AUTOSAR XML (schema 4-0-3)
package /ComponentTypes
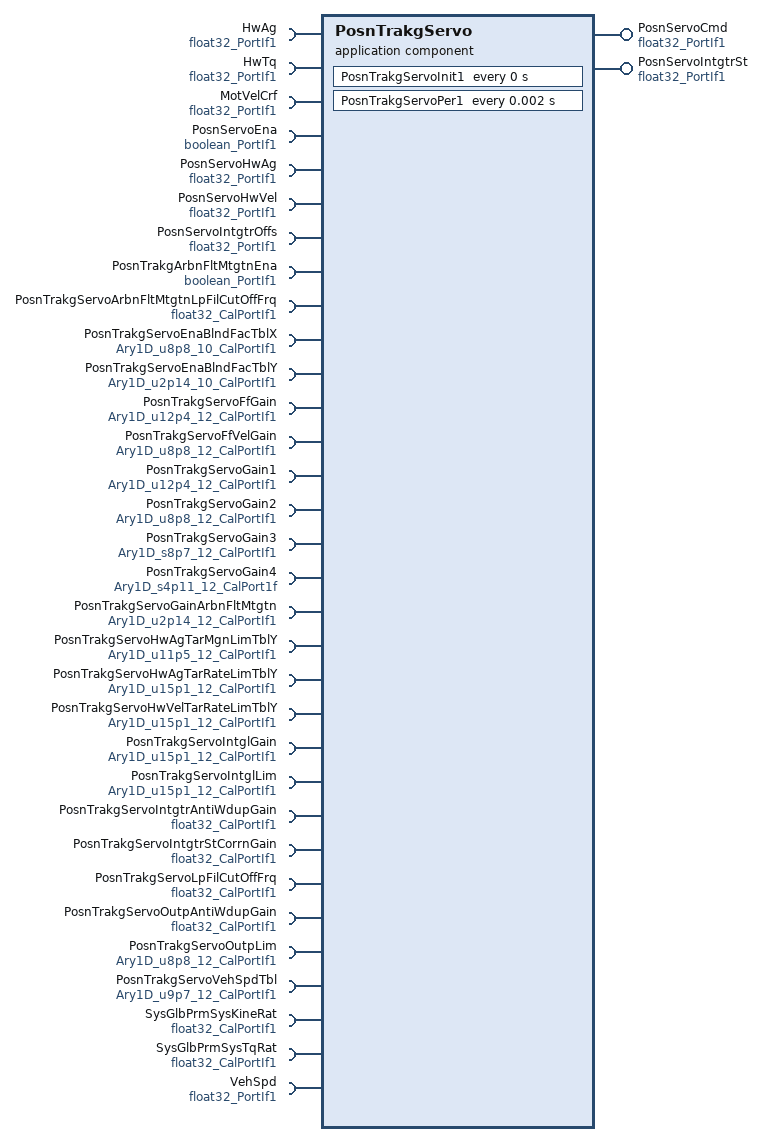
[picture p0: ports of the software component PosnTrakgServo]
  application sw component type PosnTrakgServo
    provide port PosnServoCmd: nonqueued-sender-com-spec{data-element=Val, init-value=0}, provided-interface=float32_PortIf1
    provide port PosnServoIntgtrSt: nonqueued-sender-com-spec{data-element=Val, init-value=0}, provided-interface=float32_PortIf1
    32 x require port:
      HwAg: nonqueued-receiver-com-spec{data-element=Val, filter=data-filter-type=ALWAYS, init-value=0}, required-interface=float32_PortIf1
      HwTq: nonqueued-receiver-com-spec{data-element=Val, filter=data-filter-type=ALWAYS, init-value=0}, required-interface=float32_PortIf1
      MotVelCrf: nonqueued-receiver-com-spec{data-element=Val, filter=data-filter-type=ALWAYS, init-value=0}, required-interface=float32_PortIf1
      PosnServoEna: nonqueued-receiver-com-spec{data-element=Logl, filter=data-filter-type=ALWAYS, init-value=0}, required-interface=boolean_PortIf1
      PosnServoHwAg: nonqueued-receiver-com-spec{data-element=Val, filter=data-filter-type=ALWAYS, init-value=0}, required-interface=float32_PortIf1
      PosnServoHwVel: nonqueued-receiver-com-spec{data-element=Val, filter=data-filter-type=ALWAYS, init-value=0}, required-interface=float32_PortIf1
      PosnServoIntgtrOffs: nonqueued-receiver-com-spec{data-element=Val, filter=data-filter-type=ALWAYS, init-value=0}, required-interface=float32_PortIf1
      PosnTrakgArbnFltMtgtnEna: nonqueued-receiver-com-spec{data-element=Logl, filter=data-filter-type=ALWAYS, init-value=0}, required-interface=boolean_PortIf1
      PosnTrakgServoArbnFltMtgtnLpFilCutOffFrq: parameter-require-com-spec{init-value=1, parameter=Val}, required-interface=float32_CalPortIf1
      PosnTrakgServoEnaBlndFacTblX: parameter-require-com-spec{init-value=[0, 26, 51, 77, 128, 256, 512, 768, 1024, 2560], parameter=Ary1D}, required-interface=Ary1D_u8p8_10_CalPortIf1
      PosnTrakgServoEnaBlndFacTblY: parameter-require-com-spec{init-value=[0, 164, 328, 819, 1638, 3277, 8192, 11469, 16384, 16384], parameter=Ary1D}, required-interface=Ary1D_u2p14_10_CalPortIf1
      PosnTrakgServoFfGain: parameter-require-com-spec{init-value=12 x 0, parameter=Ary1D}, required-interface=Ary1D_u12p4_12_CalPortIf1
      PosnTrakgServoFfVelGain: parameter-require-com-spec{init-value=12 x 0, parameter=Ary1D}, required-interface=Ary1D_u8p8_12_CalPortIf1
      PosnTrakgServoGain1: parameter-require-com-spec{init-value=12 x 16261, parameter=Ary1D}, required-interface=Ary1D_u12p4_12_CalPortIf1
      PosnTrakgServoGain2: parameter-require-com-spec{init-value=12 x 5780, parameter=Ary1D}, required-interface=Ary1D_u8p8_12_CalPortIf1
      PosnTrakgServoGain3: parameter-require-com-spec{init-value=12 x -326, parameter=Ary1D}, required-interface=Ary1D_s8p7_12_CalPortIf1
      PosnTrakgServoGain4: parameter-require-com-spec{init-value=12 x 222, parameter=Ary1D}, required-interface=Ary1D_s4p11_12_CalPort1f
      PosnTrakgServoGainArbnFltMtgtn: parameter-require-com-spec{init-value=[960, 960, 800, 640, 480, 320, 320, 160, 160, 160, 160, 160], parameter=Ary1D}, required-interface=Ary1D_u2p14_12_CalPortIf1
      PosnTrakgServoHwAgTarMgnLimTblY: parameter-require-com-spec{init-value=[4480, 14400, 11520, 5760, 5760, 5760, 5760, 5760, 5760, 5760, 5760, 5760], parameter=Ary1D}, required-interface=Ary1D_u11p5_12_CalPortIf1
      PosnTrakgServoHwAgTarRateLimTblY: parameter-require-com-spec{init-value=12 x 45000, parameter=Ary1D}, required-interface=Ary1D_u15p1_12_CalPortIf1
      PosnTrakgServoHwVelTarRateLimTblY: parameter-require-com-spec{init-value=12 x 45000, parameter=Ary1D}, required-interface=Ary1D_u15p1_12_CalPortIf1
      PosnTrakgServoIntglGain: parameter-require-com-spec{init-value=12 x 23646, parameter=Ary1D}, required-interface=Ary1D_u15p1_12_CalPortIf1
      PosnTrakgServoIntglLim: parameter-require-com-spec{init-value=[24000, 20000, 16000, 12000, 8000, 8000, 8000, 8000, 8000, 8000, 8000, 8000], parameter=Ary1D}, required-interface=Ary1D_u15p1_12_CalPortIf1
      PosnTrakgServoIntgtrAntiWdupGain: parameter-require-com-spec{init-value=0, parameter=Val}, required-interface=float32_CalPortIf1
      PosnTrakgServoIntgtrStCorrnGain: parameter-require-com-spec{init-value=0, parameter=Val}, required-interface=float32_CalPortIf1
      PosnTrakgServoLpFilCutOffFrq: parameter-require-com-spec{init-value=250, parameter=Val}, required-interface=float32_CalPortIf1
      PosnTrakgServoOutpAntiWdupGain: parameter-require-com-spec{init-value=0, parameter=Val}, required-interface=float32_CalPortIf1
      PosnTrakgServoOutpLim: parameter-require-com-spec{init-value=12 x 32000, parameter=Ary1D}, required-interface=Ary1D_u8p8_12_CalPortIf1
      PosnTrakgServoVehSpdTbl: parameter-require-com-spec{init-value=[0, 1280, 2560, 3840, 5120, 6400, 7680, 8960, 10240, 11520, 12800, 14080], parameter=Ary1D}, required-interface=Ary1D_u9p7_12_CalPortIf1
      SysGlbPrmSysKineRat: parameter-require-com-spec{init-value=22, parameter=Val}, required-interface=float32_CalPortIf1
      SysGlbPrmSysTqRat: parameter-require-com-spec{init-value=20, parameter=Val}, required-interface=float32_CalPortIf1
      VehSpd: nonqueued-receiver-com-spec{data-element=Val, filter=data-filter-type=ALWAYS, init-value=0}, required-interface=float32_PortIf1
    behavior PosnTrakgServo_InternalBehavior
      ar-typed-per-instance-memorys:
        20 x data, all with sw-calibration-access=READ-ONLY, type=float32:
          AntiWdupCmdPrev
          dPosnTrakgServoCmdPreLimd
          dPosnTrakgServoEnaBlndFac
          dPosnTrakgServoFfCmd
          dPosnTrakgServoHwAg
          dPosnTrakgServoHwAgErr
          dPosnTrakgServoHwAgTarLimd
          dPosnTrakgServoHwVelTarLimd
          dPosnTrakgServoIntgtrCmdLimd
          dPosnTrakgServoPtlStFbCmd
          HwTqDerivtvPrev
          HwTqPrev
          IntgtrInpPrev
          IntgtrOutpPrev
          OutpAntiWdupCmdPrev
          PosnServoCmdInpArbnFltMtgtnPrev
          PosnServoCmdOutpArbnFltMtgtnPrev
          PosnServoEnaTiPrev
          PosnServoHwAgValRateLim
          PosnServoHwVelValRateLim
      timing event PosnTrakgServo_InitEvent: start-on-event=PosnTrakgServoInit1, period=0
      timing event TMT_PosnTrakgServoPer1: start-on-event=PosnTrakgServoPer1, period=0.002
      runnable PosnTrakgServoInit1
      runnable PosnTrakgServoPer1
        data-receive-point-by-arguments:
          9 x access:
            REC_HwAg_Val: accessed-variable=HwAg.Val
            REC_HwTq_Val: accessed-variable=HwTq.Val
            REC_MotVelCrf_Val: accessed-variable=MotVelCrf.Val
            REC_PosnServoEna_Logl: accessed-variable=PosnServoEna.Logl
            REC_PosnServoHwAg_Val: accessed-variable=PosnServoHwAg.Val
            REC_PosnServoHwVel_Val: accessed-variable=PosnServoHwVel.Val
            REC_PosnServoIntgtrOffs_Val: accessed-variable=PosnServoIntgtrOffs.Val
            REC_PosnTrakgArbnFltMtgtnEna_Logl: accessed-variable=PosnTrakgArbnFltMtgtnEna.Logl
            REC_VehSpd_Val: accessed-variable=VehSpd.Val
        data-send-points:
          access SEND_PosnServoCmd_Val: accessed-variable=PosnServoCmd.Val
          access SEND_PosnServoIntgtrSt_Val: accessed-variable=PosnServoIntgtrSt.Val
  swc implementation PosnTrakgServo_Implementation: behavior=PosnTrakgServo_InternalBehavior
    code-descriptors:
      code Default: artifact-descriptors=autosar-engineering-object={short-label=Default, category=SWSRC}
